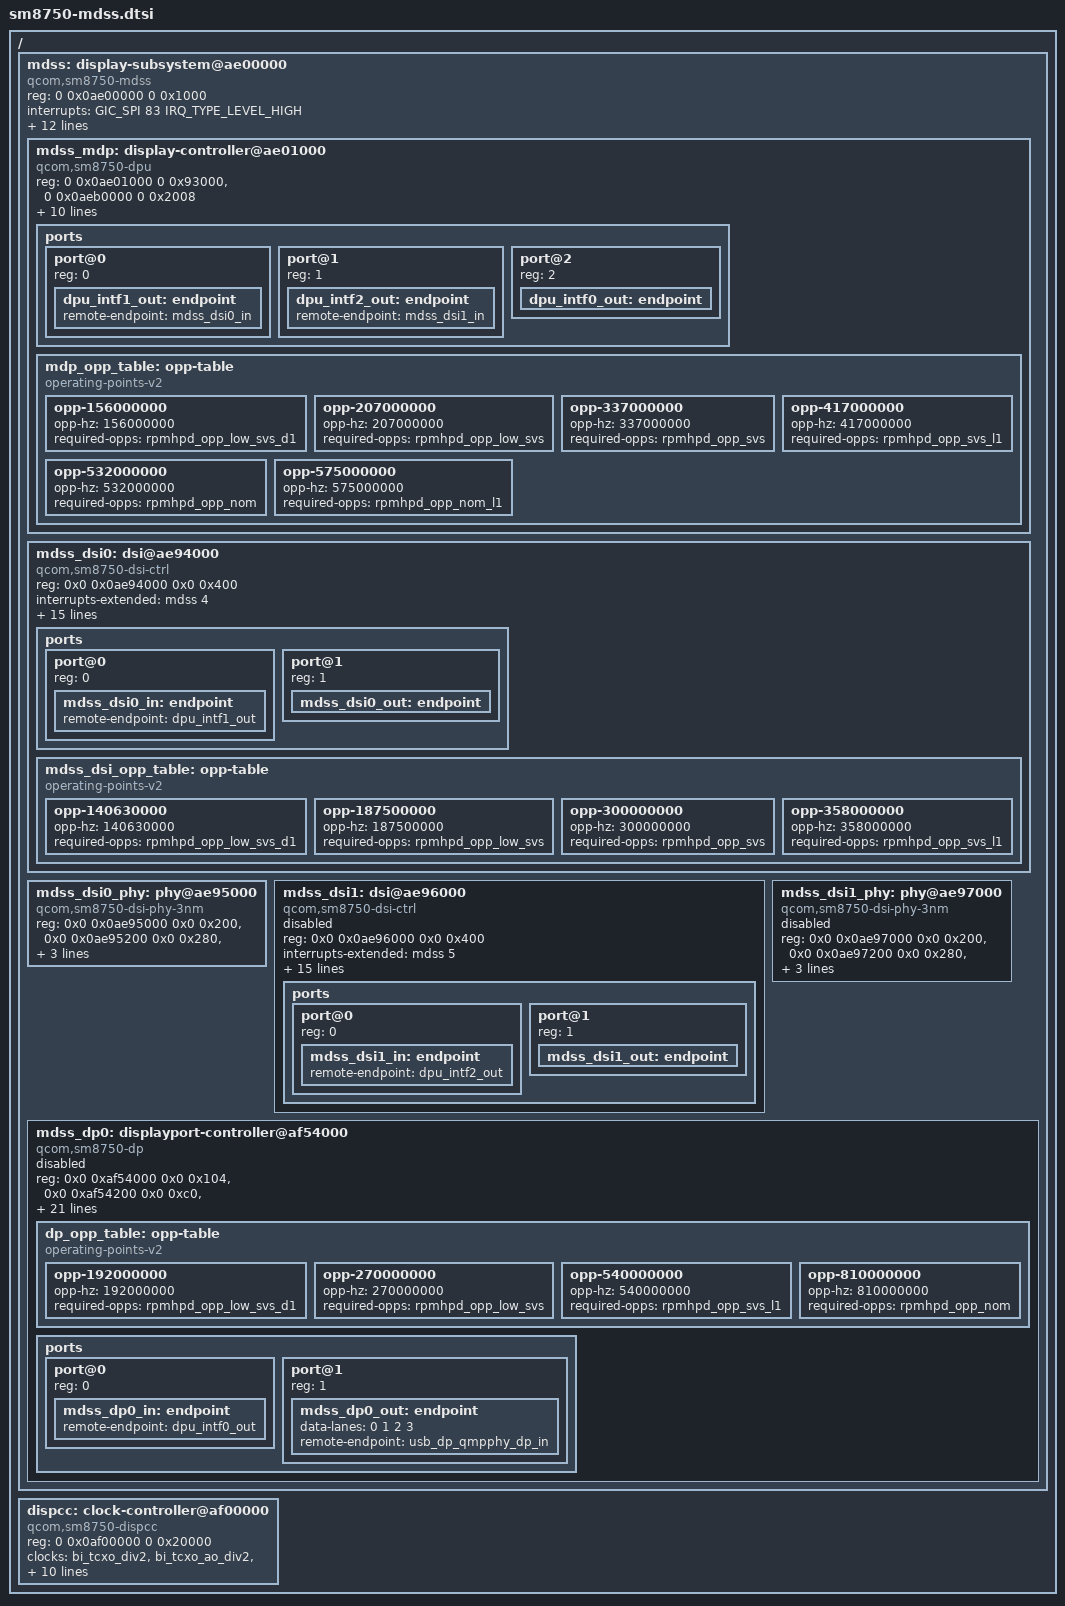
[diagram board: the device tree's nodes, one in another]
// SPDX-License-Identifier: BSD-3-Clause
/*
 * Copyright (c) 2024 Qualcomm Innovation Center, Inc. All rights reserved.
 * Copyright (c) 2025 gio3k. All rights reserved.
 *
 * Device tree for the Ayn Odin 3, based on the sm8750-mtp dts
 * Takes some inspiration from sm8750-mainline
 */

#include "sm8750.dtsi"
#include <dt-bindings/clock/qcom,sm8750-gcc.h>
#include <dt-bindings/clock/qcom,sm8750-dispcc.h>
#include <dt-bindings/clock/qcom,sm8750-gcc.h>
#include <dt-bindings/clock/qcom,dsi-phy-28nm.h>
#include <dt-bindings/interconnect/qcom,sm8750-rpmh.h>

/ {
	mdss: display-subsystem@ae00000 {
		#address-cells = <2>;
		#size-cells = <2>;
		#interrupt-cells = <1>;
		ranges;

		compatible = "qcom,sm8750-mdss";
		reg = <0 0x0ae00000 0 0x1000>;
		reg-names = "mdss";

		interrupts = <GIC_SPI 83 IRQ_TYPE_LEVEL_HIGH>;

		clocks = <&dispcc DISP_CC_MDSS_AHB_CLK>,
			 <&gcc GCC_DISP_HF_AXI_CLK>,
			 <&dispcc DISP_CC_MDSS_MDP_CLK>;

		// NOTE: Some devices have better luck with RSCC_BCR - we'll stick with CORE_BCR for now
		resets = <&dispcc DISP_CC_MDSS_CORE_BCR>;

		interconnects = <&mmss_noc MASTER_MDP QCOM_ICC_TAG_ALWAYS
				 &mc_virt SLAVE_EBI1 QCOM_ICC_TAG_ALWAYS>,
				<&gem_noc MASTER_APPSS_PROC QCOM_ICC_TAG_ACTIVE_ONLY
				 &config_noc SLAVE_DISPLAY_CFG QCOM_ICC_TAG_ACTIVE_ONLY>;
		interconnect-names = "mdp0-mem",
				     "cpu-cfg";

		power-domains = <&dispcc MDSS_GDSC>;

		iommus = <&apps_smmu 0x800 0x2>;

		interrupt-controller;

		mdss_mdp: display-controller@ae01000 {
			compatible = "qcom,sm8750-dpu";
			reg = <0 0x0ae01000 0 0x93000>,
			      <0 0x0aeb0000 0 0x2008>;
			reg-names = "mdp",
				    "vbif";

			interrupts-extended = <&mdss 0>;

			clocks = <&gcc GCC_DISP_HF_AXI_CLK>,
				 <&dispcc DISP_CC_MDSS_AHB_CLK>,
				 <&dispcc DISP_CC_MDSS_MDP_LUT_CLK>,
				 <&dispcc DISP_CC_MDSS_MDP_CLK>,
				 <&dispcc DISP_CC_MDSS_VSYNC_CLK>;
			clock-names = "nrt_bus",
				      "iface",
				      "lut",
				      "core",
				      "vsync";

			assigned-clocks = <&dispcc DISP_CC_MDSS_VSYNC_CLK>;
			assigned-clock-rates = <19200000>;

			operating-points-v2 = <&mdp_opp_table>;

			power-domains = <&rpmhpd RPMHPD_MMCX>;

			ports {
				#address-cells = <1>;
				#size-cells = <0>;

				port@0 {
					reg = <0>;

					dpu_intf1_out: endpoint {
						remote-endpoint = <&mdss_dsi0_in>;
					};
				};

				port@1 {
					reg = <1>;

					dpu_intf2_out: endpoint {
						remote-endpoint = <&mdss_dsi1_in>;
					};
				};

				port@2 {
					reg = <2>;

					dpu_intf0_out: endpoint {
						// remote-endpoint = <&mdss_dp0_in>;
					};
				};
			};

			mdp_opp_table: opp-table {
				compatible = "operating-points-v2";

				opp-156000000 {
					opp-hz = /bits/ 64 <156000000>;
					required-opps = <&rpmhpd_opp_low_svs_d1>;
				};

				opp-207000000 {
					opp-hz = /bits/ 64 <207000000>;
					required-opps = <&rpmhpd_opp_low_svs>;
				};

				opp-337000000 {
					opp-hz = /bits/ 64 <337000000>;
					required-opps = <&rpmhpd_opp_svs>;
				};

				opp-417000000 {
					opp-hz = /bits/ 64 <417000000>;
					required-opps = <&rpmhpd_opp_svs_l1>;
				};

				opp-532000000 {
					opp-hz = /bits/ 64 <532000000>;
					required-opps = <&rpmhpd_opp_nom>;
				};

				opp-575000000 {
					opp-hz = /bits/ 64 <575000000>;
					required-opps = <&rpmhpd_opp_nom_l1>;
				};
			};
		};

		mdss_dsi0: dsi@ae94000 {
			compatible = "qcom,sm8750-dsi-ctrl", "qcom,mdss-dsi-ctrl";
			reg = <0x0 0x0ae94000 0x0 0x400>;
			reg-names = "dsi_ctrl";

			interrupts-extended = <&mdss 4>;

			clocks = <&dispcc DISP_CC_MDSS_BYTE0_CLK>, 
				 <&dispcc DISP_CC_MDSS_BYTE0_INTF_CLK>,
				 <&dispcc DISP_CC_MDSS_PCLK0_CLK>, 
				 <&dispcc DISP_CC_MDSS_ESC0_CLK>,
				 <&dispcc DISP_CC_MDSS_AHB_CLK>,
				 <&gcc GCC_DISP_HF_AXI_CLK>,
				 <&mdss_dsi0_phy DSI_PIXEL_PLL_CLK>,
				 <&mdss_dsi0_phy DSI_BYTE_PLL_CLK>,
				 <&dispcc DISP_CC_ESYNC0_CLK>,
				 <&dispcc DISP_CC_OSC_CLK>,
				 <&dispcc DISP_CC_MDSS_BYTE0_CLK_SRC>,
				 <&dispcc DISP_CC_MDSS_PCLK0_CLK_SRC>;
			clock-names = "byte",
				      "byte_intf",
				      "pixel",
				      "core",
				      "iface",
				      "bus",
				      "dsi_pll_pixel",
				      "dsi_pll_byte",
				      "esync",
				      "osc",
				      "byte_src",
				      "pixel_src";

			operating-points-v2 = <&mdss_dsi_opp_table>;

			power-domains = <&rpmhpd RPMHPD_MMCX>;

			phys = <&mdss_dsi0_phy>;
			phy-names = "dsi";

			#address-cells = <1>;
			#size-cells = <0>;

			status = "okay";

			ports {
				#address-cells = <1>;
				#size-cells = <0>;

				port@0 {
					reg = <0>;

					mdss_dsi0_in: endpoint {
						remote-endpoint = <&dpu_intf1_out>;
					};
				};

				port@1 {
					reg = <1>;

					mdss_dsi0_out: endpoint {};
				};
			};

			mdss_dsi_opp_table: opp-table {
				compatible = "operating-points-v2";

				opp-140630000 {
					opp-hz = /bits/ 64 <140630000>;
					required-opps = <&rpmhpd_opp_low_svs_d1>;
				};

				opp-187500000 {
					opp-hz = /bits/ 64 <187500000>;
					required-opps = <&rpmhpd_opp_low_svs>;
				};

				opp-300000000 {
					opp-hz = /bits/ 64 <300000000>;
					required-opps = <&rpmhpd_opp_svs>;
				};

				opp-358000000 {
					opp-hz = /bits/ 64 <358000000>;
					required-opps = <&rpmhpd_opp_svs_l1>;
				};
			};
		};

		mdss_dsi0_phy: phy@ae95000 {
			compatible = "qcom,sm8750-dsi-phy-3nm";
			reg = <0x0 0x0ae95000 0x0 0x200>,
			      <0x0 0x0ae95200 0x0 0x280>,
			      <0x0 0x0ae95500 0x0 0x400>;
			reg-names = "dsi_phy",
				    "dsi_phy_lane",
				    "dsi_pll";

			clocks = <&dispcc DISP_CC_MDSS_AHB_CLK>,
				 <&bi_tcxo_div2>;
			clock-names = "iface",
				      "ref";

			#clock-cells = <1>;
			#phy-cells = <0>;

			status = "okay";
		};

		mdss_dsi1: dsi@ae96000 {
			compatible = "qcom,sm8750-dsi-ctrl", "qcom,mdss-dsi-ctrl";
			reg = <0x0 0x0ae96000 0x0 0x400>;
			reg-names = "dsi_ctrl";

			interrupts-extended = <&mdss 5>;

			clocks = <&dispcc DISP_CC_MDSS_BYTE1_CLK>,
				 <&dispcc DISP_CC_MDSS_BYTE1_INTF_CLK>,
				 <&dispcc DISP_CC_MDSS_PCLK1_CLK>,
				 <&dispcc DISP_CC_MDSS_ESC1_CLK>,
				 <&dispcc DISP_CC_MDSS_AHB_CLK>,
				 <&gcc GCC_DISP_HF_AXI_CLK>,
				 <&mdss_dsi1_phy DSI_PIXEL_PLL_CLK>,
				 <&mdss_dsi1_phy DSI_BYTE_PLL_CLK>,
				 <&dispcc DISP_CC_ESYNC1_CLK>,
				 <&dispcc DISP_CC_OSC_CLK>,
				 <&dispcc DISP_CC_MDSS_BYTE1_CLK_SRC>,
				 <&dispcc DISP_CC_MDSS_PCLK1_CLK_SRC>;
			clock-names = "byte",
				      "byte_intf",
				      "pixel",
				      "core",
				      "iface",
				      "bus",
				      "dsi_pll_pixel",
				      "dsi_pll_byte",
				      "esync",
				      "osc",
				      "byte_src",
				      "pixel_src";

			operating-points-v2 = <&mdss_dsi_opp_table>;

			power-domains = <&rpmhpd RPMHPD_MMCX>;

			phys = <&mdss_dsi1_phy>;
			phy-names = "dsi";

			#address-cells = <1>;
			#size-cells = <0>;

			status = "disabled";

			ports {
				#address-cells = <1>;
				#size-cells = <0>;

				port@0 {
					reg = <0>;

					mdss_dsi1_in: endpoint {
						remote-endpoint = <&dpu_intf2_out>;
					};
				};

				port@1 {
					reg = <1>;

					mdss_dsi1_out: endpoint {};
				};
			};
		};

		mdss_dsi1_phy: phy@ae97000 {
			compatible = "qcom,sm8750-dsi-phy-3nm";
			reg = <0x0 0x0ae97000 0x0 0x200>,
			      <0x0 0x0ae97200 0x0 0x280>,
			      <0x0 0x0ae97500 0x0 0x400>;
			reg-names = "dsi_phy",
				    "dsi_phy_lane",
				    "dsi_pll";

			clocks = <&dispcc DISP_CC_MDSS_AHB_CLK>,
				 <&bi_tcxo_div2>;
			clock-names = "iface",
				      "ref";

			#clock-cells = <1>;
			#phy-cells = <0>;

			status = "disabled";
		};

		mdss_dp0: displayport-controller@af54000 {
			compatible = "qcom,sm8750-dp", "qcom,sm8650-dp";
			reg = <0x0 0xaf54000 0x0 0x104>,
			      <0x0 0xaf54200 0x0 0xc0>,
			      <0x0 0xaf55000 0x0 0x770>,
			      <0x0 0xaf56000 0x0 0x9c>,
			      <0x0 0xaf57000 0x0 0x9c>;

			interrupts-extended = <&mdss 12>;

			clocks = <&dispcc DISP_CC_MDSS_AHB_CLK>,
				 <&dispcc DISP_CC_MDSS_DPTX0_AUX_CLK>,
				 <&dispcc DISP_CC_MDSS_DPTX0_LINK_CLK>,
				 <&dispcc DISP_CC_MDSS_DPTX0_LINK_INTF_CLK>,
				 <&dispcc DISP_CC_MDSS_DPTX0_PIXEL0_CLK>,
				 <&dispcc DISP_CC_MDSS_DPTX0_PIXEL1_CLK>;
			clock-names = "core_iface",
				      "core_aux",
				      "ctrl_link",
				      "ctrl_link_iface",
				      "stream_pixel",
				      "stream_1_pixel";

			assigned-clocks = <&dispcc DISP_CC_MDSS_DPTX0_LINK_CLK_SRC>,
					  <&dispcc DISP_CC_MDSS_DPTX0_PIXEL0_CLK_SRC>,
					  <&dispcc DISP_CC_MDSS_DPTX0_PIXEL1_CLK_SRC>;
			assigned-clock-parents = <&usb_dp_qmpphy QMP_USB43DP_DP_LINK_CLK>,
						 <&usb_dp_qmpphy QMP_USB43DP_DP_VCO_DIV_CLK>,
						 <&usb_dp_qmpphy QMP_USB43DP_DP_VCO_DIV_CLK>;

			operating-points-v2 = <&dp_opp_table>;

			power-domains = <&rpmhpd RPMHPD_MMCX>;

			phys = <&usb_dp_qmpphy QMP_USB43DP_DP_PHY>;
			phy-names = "dp";

			#sound-dai-cells = <0>;

			status = "disabled";

			dp_opp_table: opp-table {
				compatible = "operating-points-v2";

				opp-192000000 {
					opp-hz = /bits/ 64 <192000000>;
					required-opps = <&rpmhpd_opp_low_svs_d1>;
				};

				opp-270000000 {
					opp-hz = /bits/ 64 <270000000>;
					required-opps = <&rpmhpd_opp_low_svs>;
				};

				opp-540000000 {
					opp-hz = /bits/ 64 <540000000>;
					required-opps = <&rpmhpd_opp_svs_l1>;
				};

				opp-810000000 {
					opp-hz = /bits/ 64 <810000000>;
					required-opps = <&rpmhpd_opp_nom>;
				};
			};

			ports {
				#address-cells = <1>;
				#size-cells = <0>;

				port@0 {
					reg = <0>;

					mdss_dp0_in: endpoint {
						remote-endpoint = <&dpu_intf0_out>;
					};
				};

				port@1 {
					reg = <1>;

					mdss_dp0_out: endpoint {
						data-lanes = <0 1 2 3>;
						remote-endpoint = <&usb_dp_qmpphy_dp_in>;
					};
				};
			};
		};
	};

	dispcc: clock-controller@af00000 {
		compatible = "qcom,sm8750-dispcc";
		reg = <0 0x0af00000 0 0x20000>;

		clocks = <&bi_tcxo_div2>,
			 <&bi_tcxo_ao_div2>,
			 <&gcc GCC_DISP_AHB_CLK>,
			 <&sleep_clk>,
			 <&mdss_dsi0_phy DSI_BYTE_PLL_CLK>,
			 <&mdss_dsi0_phy DSI_PIXEL_PLL_CLK>,
			 <&mdss_dsi1_phy DSI_BYTE_PLL_CLK>,
			 <&mdss_dsi1_phy DSI_PIXEL_PLL_CLK>,
			 <&usb_dp_qmpphy QMP_USB43DP_DP_LINK_CLK>,
			 <&usb_dp_qmpphy QMP_USB43DP_DP_VCO_DIV_CLK>,
			 <0>, /* dp1 */
			 <0>,
			 <0>, /* dp2 */
			 <0>,
			 <0>, /* dp3 */
			 <0>;

		power-domains = <&rpmhpd RPMHPD_MMCX>;
		required-opps = <&rpmhpd_opp_low_svs>;

		#clock-cells = <1>;
		#reset-cells = <1>;
		#power-domain-cells = <1>;
	};
};
